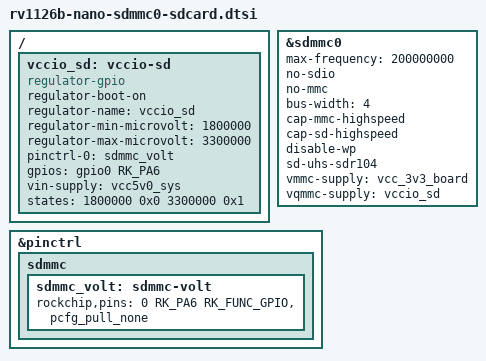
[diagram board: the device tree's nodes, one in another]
// SPDX-License-Identifier: (GPL-2.0+ OR MIT)
/*
 * Copyright (c) 2025 Guangzhou EASY EAI Technology Co., Ltd.
 */

/{
	vccio_sd: vccio-sd {
		compatible = "regulator-gpio";
		regulator-boot-on;
		regulator-name = "vccio_sd";
		regulator-min-microvolt = <1800000>;
		regulator-max-microvolt = <3300000>;
		pinctrl-names = "default";
		pinctrl-0 = <&sdmmc_volt>;
		gpios = <&gpio0 RK_PA6 GPIO_ACTIVE_HIGH>;
		vin-supply = <&vcc5v0_sys>;
		states = <1800000 0x0
			  3300000 0x1>;
	};
};

&sdmmc0 {
	max-frequency = <200000000>;
	no-sdio;
	no-mmc;
	bus-width = <4>;
	cap-mmc-highspeed;
	cap-sd-highspeed;
	disable-wp;
	sd-uhs-sdr104;
	vmmc-supply = <&vcc_3v3_board>;
	vqmmc-supply = <&vccio_sd>;
	status = "okay";
};

&pinctrl {
	sdmmc {
		/omit-if-no-ref/
		sdmmc_volt: sdmmc-volt {
			rockchip,pins = <0 RK_PA6 RK_FUNC_GPIO &pcfg_pull_none>;
		};
	};
};
